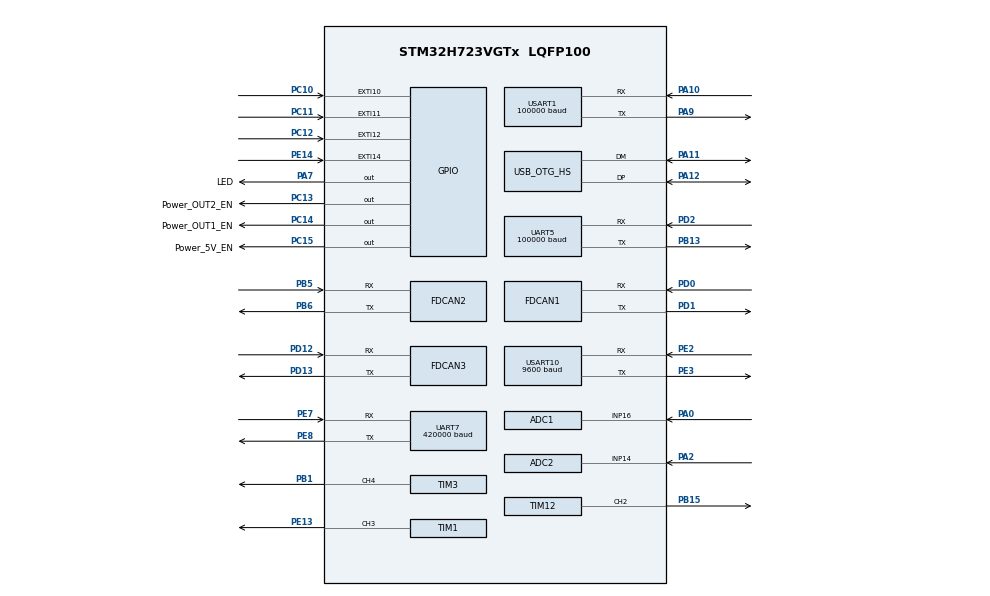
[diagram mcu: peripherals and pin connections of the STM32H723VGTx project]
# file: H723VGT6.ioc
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ADC1.Channel-0\#ChannelRegularConversion=ADC_CHANNEL_16
ADC1.ClockPrescaler=ADC_CLOCK_SYNC_PCLK_DIV1
ADC1.ContinuousConvMode=ENABLE
ADC1.ConversionDataManagement=ADC_CONVERSIONDATA_DMA_CIRCULAR
ADC1.NbrOfConversion=1
ADC1.NbrOfConversionFlag=1
ADC1.OffsetNumber-0\#ChannelRegularConversion=ADC_OFFSET_NONE
ADC1.OffsetSignedSaturation-0\#ChannelRegularConversion=DISABLE
ADC1.Rank-0\#ChannelRegularConversion=1
ADC1.Ratio=1
ADC1.Resolution=ADC_RESOLUTION_12B
ADC1.SamplingTime-0\#ChannelRegularConversion=ADC_SAMPLETIME_64CYCLES_5
ADC1.master=1
ADC2.Channel-0\#ChannelRegularConversion=ADC_CHANNEL_14
ADC2.ClockPrescaler=ADC_CLOCK_SYNC_PCLK_DIV1
ADC2.ContinuousConvMode=ENABLE
ADC2.ConversionDataManagement=ADC_CONVERSIONDATA_DMA_CIRCULAR
ADC2.LowPowerAutoWait=ENABLE
ADC2.NbrOfConversionFlag=1
ADC2.OffsetNumber-0\#ChannelRegularConversion=ADC_OFFSET_NONE
ADC2.OffsetSignedSaturation-0\#ChannelRegularConversion=DISABLE
ADC2.Rank-0\#ChannelRegularConversion=1
ADC2.Resolution=ADC_RESOLUTION_12B
ADC2.SamplingTime-0\#ChannelRegularConversion=ADC_SAMPLETIME_64CYCLES_5
CORTEX_M7.default_mode_Activation=0
Dma.ADC1.6.Direction=DMA_PERIPH_TO_MEMORY
Dma.ADC1.6.EventEnable=DISABLE
Dma.ADC1.6.FIFOMode=DMA_FIFOMODE_DISABLE
Dma.ADC1.6.Instance=DMA1_Stream5
Dma.ADC1.6.MemDataAlignment=DMA_MDATAALIGN_HALFWORD
Dma.ADC1.6.MemInc=DMA_MINC_ENABLE
Dma.ADC1.6.Mode=DMA_CIRCULAR
Dma.ADC1.6.PeriphDataAlignment=DMA_PDATAALIGN_HALFWORD
Dma.ADC1.6.PeriphInc=DMA_PINC_DISABLE
Dma.ADC1.6.Polarity=HAL_DMAMUX_REQ_GEN_RISING
Dma.ADC1.6.Priority=DMA_PRIORITY_HIGH
Dma.ADC1.6.RequestNumber=1
Dma.ADC1.6.SignalID=NONE
Dma.ADC1.6.SyncEnable=DISABLE
Dma.ADC1.6.SyncPolarity=HAL_DMAMUX_SYNC_NO_EVENT
Dma.ADC1.6.SyncRequestNumber=1
Dma.ADC1.6.SyncSignalID=NONE
Dma.ADC2.7.Direction=DMA_PERIPH_TO_MEMORY
Dma.ADC2.7.EventEnable=DISABLE
Dma.ADC2.7.FIFOMode=DMA_FIFOMODE_DISABLE
Dma.ADC2.7.Instance=DMA1_Stream6
Dma.ADC2.7.MemDataAlignment=DMA_MDATAALIGN_HALFWORD
Dma.ADC2.7.MemInc=DMA_MINC_ENABLE
Dma.ADC2.7.Mode=DMA_CIRCULAR
Dma.ADC2.7.PeriphDataAlignment=DMA_PDATAALIGN_HALFWORD
Dma.ADC2.7.PeriphInc=DMA_PINC_DISABLE
Dma.ADC2.7.Polarity=HAL_DMAMUX_REQ_GEN_RISING
Dma.ADC2.7.Priority=DMA_PRIORITY_HIGH
Dma.ADC2.7.RequestNumber=1
Dma.ADC2.7.SignalID=NONE
Dma.ADC2.7.SyncEnable=DISABLE
Dma.ADC2.7.SyncPolarity=HAL_DMAMUX_SYNC_NO_EVENT
Dma.ADC2.7.SyncRequestNumber=1
Dma.ADC2.7.SyncSignalID=NONE
Dma.Request0=USART1_RX
Dma.Request1=USART1_TX
Dma.Request2=USART10_RX
Dma.Request3=USART10_TX
Dma.Request4=UART5_RX
Dma.Request5=UART7_RX
Dma.Request6=ADC1
Dma.Request7=ADC2
Dma.UART5_RX.4.Direction=DMA_PERIPH_TO_MEMORY
Dma.UART5_RX.4.EventEnable=DISABLE
Dma.UART5_RX.4.FIFOMode=DMA_FIFOMODE_DISABLE
Dma.UART5_RX.4.Instance=DMA2_Stream0
Dma.UART5_RX.4.MemDataAlignment=DMA_MDATAALIGN_BYTE
Dma.UART5_RX.4.MemInc=DMA_MINC_ENABLE
Dma.UART5_RX.4.Mode=DMA_CIRCULAR
Dma.UART5_RX.4.PeriphDataAlignment=DMA_PDATAALIGN_BYTE
Dma.UART5_RX.4.PeriphInc=DMA_PINC_DISABLE
Dma.UART5_RX.4.Polarity=HAL_DMAMUX_REQ_GEN_RISING
Dma.UART5_RX.4.Priority=DMA_PRIORITY_VERY_HIGH
Dma.UART5_RX.4.RequestNumber=1
Dma.UART5_RX.4.SignalID=NONE
Dma.UART5_RX.4.SyncEnable=DISABLE
Dma.UART5_RX.4.SyncPolarity=HAL_DMAMUX_SYNC_NO_EVENT
Dma.UART5_RX.4.SyncRequestNumber=1
Dma.UART5_RX.4.SyncSignalID=NONE
Dma.UART7_RX.5.Direction=DMA_PERIPH_TO_MEMORY
Dma.UART7_RX.5.EventEnable=DISABLE
Dma.UART7_RX.5.FIFOMode=DMA_FIFOMODE_DISABLE
Dma.UART7_RX.5.Instance=DMA1_Stream0
Dma.UART7_RX.5.MemDataAlignment=DMA_MDATAALIGN_BYTE
Dma.UART7_RX.5.MemInc=DMA_MINC_ENABLE
Dma.UART7_RX.5.Mode=DMA_CIRCULAR
Dma.UART7_RX.5.PeriphDataAlignment=DMA_PDATAALIGN_BYTE
Dma.UART7_RX.5.PeriphInc=DMA_PINC_DISABLE
Dma.UART7_RX.5.Polarity=HAL_DMAMUX_REQ_GEN_RISING
Dma.UART7_RX.5.Priority=DMA_PRIORITY_VERY_HIGH
Dma.UART7_RX.5.RequestNumber=1
Dma.UART7_RX.5.SignalID=NONE
Dma.UART7_RX.5.SyncEnable=DISABLE
Dma.UART7_RX.5.SyncPolarity=HAL_DMAMUX_SYNC_NO_EVENT
Dma.UART7_RX.5.SyncRequestNumber=1
Dma.UART7_RX.5.SyncSignalID=NONE
Dma.USART10_RX.2.Direction=DMA_PERIPH_TO_MEMORY
Dma.USART10_RX.2.EventEnable=DISABLE
Dma.USART10_RX.2.FIFOMode=DMA_FIFOMODE_DISABLE
Dma.USART10_RX.2.Instance=DMA1_Stream3
Dma.USART10_RX.2.MemDataAlignment=DMA_MDATAALIGN_BYTE
Dma.USART10_RX.2.MemInc=DMA_MINC_ENABLE
Dma.USART10_RX.2.Mode=DMA_NORMAL
Dma.USART10_RX.2.PeriphDataAlignment=DMA_PDATAALIGN_BYTE
Dma.USART10_RX.2.PeriphInc=DMA_PINC_DISABLE
Dma.USART10_RX.2.Polarity=HAL_DMAMUX_REQ_GEN_RISING
Dma.USART10_RX.2.Priority=DMA_PRIORITY_LOW
Dma.USART10_RX.2.RequestNumber=1
Dma.USART10_RX.2.SignalID=NONE
Dma.USART10_RX.2.SyncEnable=DISABLE
Dma.USART10_RX.2.SyncPolarity=HAL_DMAMUX_SYNC_NO_EVENT
Dma.USART10_RX.2.SyncRequestNumber=1
Dma.USART10_RX.2.SyncSignalID=NONE
Dma.USART10_TX.3.Direction=DMA_MEMORY_TO_PERIPH
Dma.USART10_TX.3.EventEnable=DISABLE
Dma.USART10_TX.3.FIFOMode=DMA_FIFOMODE_DISABLE
Dma.USART10_TX.3.Instance=DMA1_Stream4
Dma.USART10_TX.3.MemDataAlignment=DMA_MDATAALIGN_BYTE
Dma.USART10_TX.3.MemInc=DMA_MINC_ENABLE
Dma.USART10_TX.3.Mode=DMA_NORMAL
Dma.USART10_TX.3.PeriphDataAlignment=DMA_PDATAALIGN_BYTE
Dma.USART10_TX.3.PeriphInc=DMA_PINC_DISABLE
Dma.USART10_TX.3.Polarity=HAL_DMAMUX_REQ_GEN_RISING
Dma.USART10_TX.3.Priority=DMA_PRIORITY_LOW
Dma.USART10_TX.3.RequestNumber=1
Dma.USART10_TX.3.SignalID=NONE
Dma.USART10_TX.3.SyncEnable=DISABLE
Dma.USART10_TX.3.SyncPolarity=HAL_DMAMUX_SYNC_NO_EVENT
Dma.USART10_TX.3.SyncRequestNumber=1
Dma.USART10_TX.3.SyncSignalID=NONE
Dma.USART1_RX.0.Direction=DMA_PERIPH_TO_MEMORY
Dma.USART1_RX.0.EventEnable=DISABLE
Dma.USART1_RX.0.FIFOMode=DMA_FIFOMODE_DISABLE
Dma.USART1_RX.0.Instance=DMA1_Stream1
Dma.USART1_RX.0.MemDataAlignment=DMA_MDATAALIGN_BYTE
Dma.USART1_RX.0.MemInc=DMA_MINC_ENABLE
Dma.USART1_RX.0.Mode=DMA_NORMAL
Dma.USART1_RX.0.PeriphDataAlignment=DMA_PDATAALIGN_BYTE
Dma.USART1_RX.0.PeriphInc=DMA_PINC_DISABLE
Dma.USART1_RX.0.Polarity=HAL_DMAMUX_REQ_GEN_RISING
Dma.USART1_RX.0.Priority=DMA_PRIORITY_LOW
Dma.USART1_RX.0.RequestNumber=1
Dma.USART1_RX.0.SignalID=NONE
Dma.USART1_RX.0.SyncEnable=DISABLE
Dma.USART1_RX.0.SyncPolarity=HAL_DMAMUX_SYNC_NO_EVENT
Dma.USART1_RX.0.SyncRequestNumber=1
Dma.USART1_RX.0.SyncSignalID=NONE
Dma.USART1_TX.1.Direction=DMA_MEMORY_TO_PERIPH
Dma.USART1_TX.1.EventEnable=DISABLE
Dma.USART1_TX.1.FIFOMode=DMA_FIFOMODE_DISABLE
Dma.USART1_TX.1.Instance=DMA1_Stream2
Dma.USART1_TX.1.MemDataAlignment=DMA_MDATAALIGN_BYTE
Dma.USART1_TX.1.MemInc=DMA_MINC_ENABLE
Dma.USART1_TX.1.Mode=DMA_NORMAL
Dma.USART1_TX.1.PeriphDataAlignment=DMA_PDATAALIGN_BYTE
Dma.USART1_TX.1.PeriphInc=DMA_PINC_DISABLE
Dma.USART1_TX.1.Polarity=HAL_DMAMUX_REQ_GEN_RISING
Dma.USART1_TX.1.Priority=DMA_PRIORITY_LOW
Dma.USART1_TX.1.RequestNumber=1
Dma.USART1_TX.1.SignalID=NONE
Dma.USART1_TX.1.SyncEnable=DISABLE
Dma.USART1_TX.1.SyncPolarity=HAL_DMAMUX_SYNC_NO_EVENT
Dma.USART1_TX.1.SyncRequestNumber=1
Dma.USART1_TX.1.SyncSignalID=NONE
FDCAN1.AutoRetransmission=ENABLE
FDCAN1.CalculateBaudRateNominal=1000000
FDCAN1.CalculateTimeBitNominal=1000
FDCAN1.CalculateTimeQuantumNominal=25.0
FDCAN1.DataPrescaler=3
FDCAN1.DataSyncJumpWidth=10
FDCAN1.DataTimeSeg1=29
FDCAN1.DataTimeSeg2=10
FDCAN1.ExtFiltersNbr=12
FDCAN1.MessageRAMOffset=0
FDCAN1.NominalPrescaler=3
FDCAN1.NominalSyncJumpWidth=10
FDCAN1.NominalTimeSeg1=29
FDCAN1.NominalTimeSeg2=10
FDCAN1.ProtocolException=ENABLE
FDCAN1.RxFifo0ElmtsNbr=8
FDCAN1.RxFifo1ElmtsNbr=8
FDCAN1.StdFiltersNbr=12
FDCAN1.TxFifoQueueElmtsNbr=32
FDCAN2.AutoRetransmission=ENABLE
FDCAN2.CalculateBaudRateNominal=1000000
FDCAN2.CalculateTimeBitNominal=1000
FDCAN2.CalculateTimeQuantumNominal=25.0
FDCAN2.DataPrescaler=3
FDCAN2.DataSyncJumpWidth=10
FDCAN2.DataTimeSeg1=29
FDCAN2.DataTimeSeg2=10
FDCAN2.ExtFiltersNbr=12
FDCAN2.MessageRAMOffset=0
FDCAN2.NominalPrescaler=3
FDCAN2.NominalSyncJumpWidth=10
FDCAN2.NominalTimeSeg1=29
FDCAN2.NominalTimeSeg2=10
FDCAN2.ProtocolException=ENABLE
FDCAN2.RxFifo0ElmtsNbr=8
FDCAN2.RxFifo1ElmtsNbr=8
FDCAN2.StdFiltersNbr=12
FDCAN2.TxFifoQueueElmtsNbr=32
FDCAN3.AutoRetransmission=ENABLE
FDCAN3.CalculateBaudRateNominal=1000000
FDCAN3.CalculateTimeBitNominal=1000
FDCAN3.CalculateTimeQuantumNominal=25.0
FDCAN3.DataPrescaler=3
FDCAN3.DataSyncJumpWidth=10
FDCAN3.DataTimeSeg1=29
FDCAN3.DataTimeSeg2=10
FDCAN3.ExtFiltersNbr=0
FDCAN3.MessageRAMOffset=1700
FDCAN3.NominalPrescaler=3
FDCAN3.NominalSyncJumpWidth=10
FDCAN3.NominalTimeSeg1=29
FDCAN3.NominalTimeSeg2=10
FDCAN3.ProtocolException=ENABLE
FDCAN3.RxFifo0ElmtsNbr=8
FDCAN3.RxFifo1ElmtsNbr=8
FDCAN3.StdFiltersNbr=0
FDCAN3.TxFifoQueueElmtsNbr=32
Mcu.Family=STM32H7
Mcu.Name=STM32H723VGTx
Mcu.Package=LQFP100
NVIC.DMA1_Stream0_IRQn=true\:0\:0\:false\:false\:true\:false\:true\:true
NVIC.DMA1_Stream1_IRQn=true\:0\:0\:false\:false\:true\:false\:true\:true
NVIC.DMA1_Stream2_IRQn=true\:0\:0\:false\:false\:true\:false\:true\:true
NVIC.DMA1_Stream3_IRQn=true\:0\:0\:false\:false\:true\:false\:true\:true
NVIC.DMA1_Stream4_IRQn=true\:0\:0\:false\:false\:true\:false\:true\:true
NVIC.DMA1_Stream5_IRQn=true\:0\:0\:false\:false\:true\:false\:true\:true
NVIC.DMA1_Stream6_IRQn=true\:0\:0\:false\:false\:true\:false\:true\:true
NVIC.DMA2_Stream0_IRQn=true\:0\:0\:false\:false\:true\:false\:true\:true
NVIC.EXTI15_10_IRQn=true\:0\:0\:false\:false\:true\:true\:true\:true
NVIC.FDCAN1_IT0_IRQn=true\:0\:0\:false\:false\:true\:true\:true\:true
NVIC.FDCAN2_IT0_IRQn=true\:0\:0\:false\:false\:true\:true\:true\:true
NVIC.FDCAN3_IT0_IRQn=true\:0\:0\:false\:false\:true\:true\:true\:true
NVIC.OTG_HS_IRQn=true\:0\:0\:false\:false\:true\:true\:true\:true
NVIC.PriorityGroup=NVIC_PRIORITYGROUP_4
NVIC.TIM2_IRQn=true\:0\:0\:false\:false\:true\:true\:true\:true
NVIC.TIM4_IRQn=true\:0\:0\:false\:false\:true\:true\:true\:true
NVIC.TIM5_IRQn=true\:1\:0\:true\:false\:true\:true\:true\:true
NVIC.UART5_IRQn=true\:0\:0\:false\:false\:true\:true\:true\:true
NVIC.USART10_IRQn=true\:0\:0\:false\:false\:true\:true\:true\:true
NVIC.USART1_IRQn=true\:0\:0\:false\:false\:true\:true\:true\:true
PA0.Mode=IN16-Single-Ended
PA0.Signal=ADC1_INP16
PA10.Mode=Asynchronous
PA10.Signal=USART1_RX
PA11.Mode=Device_Only_FS
PA11.Signal=USB_OTG_HS_DM
PA12.Mode=Device_Only_FS
PA12.Signal=USB_OTG_HS_DP
PA13(JTMS/SWDIO).Mode=Serial_Wire
PA13(JTMS/SWDIO).Signal=DEBUG_JTMS-SWDIO
PA14(JTCK/SWCLK).Mode=Serial_Wire
PA14(JTCK/SWCLK).Signal=DEBUG_JTCK-SWCLK
PA2.Signal=ADCx_INP14
PA7.GPIO_Label=LED
PA7.Signal=GPIO_Output
PA9.Mode=Asynchronous
PA9.Signal=USART1_TX
PB1.Signal=S_TIM3_CH4
PB13.Mode=Asynchronous
PB13.Signal=UART5_TX
PB15.Signal=S_TIM12_CH2
PB5.Mode=FDCAN_Activate
PB5.Signal=FDCAN2_RX
PB6.Mode=FDCAN_Activate
PB6.Signal=FDCAN2_TX
PC10.GPIO_ModeDefaultEXTI=GPIO_MODE_IT_FALLING
PC10.GPIO_PuPd=GPIO_PULLUP
PC10.Signal=GPXTI10
PC11.GPIO_ModeDefaultEXTI=GPIO_MODE_IT_FALLING
PC11.GPIO_PuPd=GPIO_PULLUP
PC11.Signal=GPXTI11
PC12.GPIO_ModeDefaultEXTI=GPIO_MODE_IT_FALLING
PC12.GPIO_PuPd=GPIO_PULLUP
PC12.Signal=GPXTI12
PC13.GPIO_Label=Power_OUT2_EN
PC13.GPIO_PuPd=GPIO_PULLDOWN
PC13.Signal=GPIO_Output
PC14-OSC32_IN.GPIO_Label=Power_OUT1_EN
PC14-OSC32_IN.GPIO_PuPd=GPIO_PULLDOWN
PC14-OSC32_IN.PinState=GPIO_PIN_SET
PC14-OSC32_IN.Signal=GPIO_Output
PC15-OSC32_OUT.GPIO_Label=Power_5V_EN
PC15-OSC32_OUT.GPIO_PuPd=GPIO_PULLUP
PC15-OSC32_OUT.Signal=GPIO_Output
PD0.Mode=FDCAN_Activate
PD0.Signal=FDCAN1_RX
PD1.Mode=FDCAN_Activate
PD1.Signal=FDCAN1_TX
PD12.Mode=FDCAN_Activate
PD12.Signal=FDCAN3_RX
PD13.Mode=FDCAN_Activate
PD13.Signal=FDCAN3_TX
PD2.Mode=Asynchronous
PD2.Signal=UART5_RX
PE13.Signal=S_TIM1_CH3
PE14.GPIO_ModeDefaultEXTI=GPIO_MODE_IT_FALLING
PE14.GPIO_PuPd=GPIO_PULLUP
PE14.Signal=GPXTI14
PE2.Mode=Asynchronous
PE2.Signal=USART10_RX
PE3.Mode=Asynchronous
PE3.Signal=USART10_TX
PE7.Mode=Asynchronous
PE7.Signal=UART7_RX
PE8.Mode=Asynchronous
PE8.Signal=UART7_TX
PH0-OSC_IN.Mode=HSE-External-Oscillator
PH0-OSC_IN.Signal=RCC_OSC_IN
PH1-OSC_OUT.Mode=HSE-External-Oscillator
PH1-OSC_OUT.Signal=RCC_OSC_OUT
ProjectManager.HeapSize=0x400
ProjectManager.StackSize=0x2000
ProjectManager.TargetToolchain=CMake
RCC.ADCFreq_Value=100000000
RCC.APB1Freq_Value=120000000
RCC.APB2Freq_Value=120000000
RCC.APB3Freq_Value=120000000
RCC.APB4Freq_Value=120000000
RCC.CortexFreq_Value=480000000
RCC.D1PPRE=RCC_APB3_DIV2
RCC.D2PPRE1=RCC_APB1_DIV2
RCC.D2PPRE2=RCC_APB2_DIV2
RCC.D3PPRE=RCC_APB4_DIV2
RCC.DIVM1=2
RCC.DIVM2=24
RCC.DIVN1=40
RCC.DIVN2=200
RCC.DIVP1=1
RCC.DIVQ1=4
RCC.HCLKFreq_Value=240000000
RCC.HPRE=RCC_HCLK_DIV2
RCC.HSE_VALUE=24000000
RCC.PLL2FRACN=0
RCC.PLL3FRACN=0
RCC.PLLFRACN=0
RCC.PLLSourceVirtual=RCC_PLLSOURCE_HSE
RCC.SYSCLKFreq_VALUE=480000000
RCC.SYSCLKSource=RCC_SYSCLKSOURCE_PLLCLK
RCC.USBCLockSelection=RCC_USBCLKSOURCE_HSI48
RCC.USBFreq_Value=48000000
SH.ADCx_INP14.0=ADC2_INP14,IN14-Single-Ended
SH.S_TIM12_CH2.0=TIM12_CH2,PWM Generation2 CH2
SH.S_TIM1_CH3.0=TIM1_CH3,PWM Generation3 CH3
SH.S_TIM3_CH4.0=TIM3_CH4,PWM Generation4 CH4
TIM1.Channel-PWM\ Generation3\ CH3=TIM_CHANNEL_3
TIM1.Period=20000-1
TIM1.Prescaler=239
TIM12.AutoReloadPreload=TIM_AUTORELOAD_PRELOAD_ENABLE
TIM12.Channel-PWM\ Generation2\ CH2=TIM_CHANNEL_2
TIM12.Period=1000-1
TIM12.Prescaler=240-1
TIM2.AutoReloadPreload=TIM_AUTORELOAD_PRELOAD_ENABLE
TIM2.Period=1000-1
TIM2.Prescaler=240-1
TIM3.Channel-PWM\ Generation4\ CH4=TIM_CHANNEL_4
TIM3.OCFastMode_PWM-PWM\ Generation4\ CH4=TIM_OCFAST_ENABLE
TIM3.Period=255
TIM4.Period=100-1
TIM4.Prescaler=240-1
TIM5.Period=1000-1
TIM5.Prescaler=240-1
UART5.BaudRate=100000
UART5.Mode=MODE_RX
UART5.Parity=PARITY_EVEN
UART5.StopBits=UART_STOPBITS_2
UART5.WordLength=WORDLENGTH_9B
UART7.BaudRate=420000
USART1.BaudRate=100000
USART1.Parity=PARITY_EVEN
USART1.RxPinLevelInvertParam=ADVFEATURE_RXINV_ENABLE
USART1.StopBits=STOPBITS_2
USART1.VirtualMode-Asynchronous=VM_ASYNC
USART10.BaudRate=9600
USART10.VirtualMode=VM_ASYNC
USB_DEVICE.CLASS_NAME_HS=CDC
USB_DEVICE.VirtualMode=Cdc
USB_DEVICE.VirtualModeHS=Cdc_HS
USB_OTG_HS.VirtualMode-Device_Only_FS=Device_Only_FS
VP_MEMORYMAP_VS_MEMORYMAP.Mode=CurAppReg
VP_TIM2_VS_ClockSourceINT.Mode=Internal
VP_TIM4_VS_ClockSourceINT.Mode=Internal
VP_TIM5_VS_ClockSourceINT.Mode=Internal
VP_USB_DEVICE_VS_USB_DEVICE_CDC_HS.Mode=CDC_HS
board=custom

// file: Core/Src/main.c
/* USER CODE BEGIN Header */
/**
  ******************************************************************************
  * @file           : main.c
  * @brief          : Main program body
  ******************************************************************************
  * @attention
  *
  * Copyright (c) 2026 STMicroelectronics.
  * All rights reserved.
  *
  * This software is licensed under terms that can be found in the LICENSE file
  * in the root directory of this software component.
  * If no LICENSE file comes with this software, it is provided AS-IS.
  *
  ******************************************************************************
  */
/* USER CODE END Header */
#include "main.h"
#include "adc.h"
#include "dma.h"
#include "fdcan.h"
#include "tim.h"
#include "usart.h"
#include "usb_device.h"
#include "gpio.h"

/* USER CODE BEGIN Includes */
#include "tsk_config_and_callback.h"
/* USER CODE END Includes */

void SystemClock_Config(void);

int main(void)
{

  /* MCU Configuration--------------------------------------------------------*/

  /* Reset of all peripherals, Initializes the Flash interface and the Systick. */
  HAL_Init();

  /* Configure the system clock */
  SystemClock_Config();

  /* Initialize all configured peripherals */
  MX_GPIO_Init();
  MX_DMA_Init();
  MX_TIM5_Init();
  MX_FDCAN1_Init();
  MX_TIM3_Init();
  MX_TIM12_Init();
  MX_FDCAN2_Init();
  MX_FDCAN3_Init();
  MX_UART5_Init();
  MX_USART1_UART_Init();
  MX_USART10_UART_Init();
  MX_TIM4_Init();
  MX_UART7_Init();
  MX_ADC1_Init();
  MX_USB_DEVICE_Init();
  MX_TIM1_Init();
  MX_ADC2_Init();
  MX_TIM2_Init();
  /* USER CODE BEGIN 2 */
  TaskInit();
  /* USER CODE END 2 */

  /* Infinite loop */
  while (1)
  {

    /* USER CODE BEGIN 3 */
    TaskLoop();
  }
  /* USER CODE END 3 */
}

void SystemClock_Config(void)
{
  RCC_OscInitTypeDef RCC_OscInitStruct = {0};
  RCC_ClkInitTypeDef RCC_ClkInitStruct = {0};

  /** Supply configuration update enable
  */
  HAL_PWREx_ConfigSupply(PWR_LDO_SUPPLY);

  /** Configure the main internal regulator output voltage
  */
  __HAL_PWR_VOLTAGESCALING_CONFIG(PWR_REGULATOR_VOLTAGE_SCALE0);

  while(!__HAL_PWR_GET_FLAG(PWR_FLAG_VOSRDY)) {}

  /** Initializes the RCC Oscillators according to the specified parameters
  * in the RCC_OscInitTypeDef structure.
  */
  RCC_OscInitStruct.OscillatorType = RCC_OSCILLATORTYPE_HSI48|RCC_OSCILLATORTYPE_HSE;
  RCC_OscInitStruct.HSEState = RCC_HSE_ON;
  RCC_OscInitStruct.HSI48State = RCC_HSI48_ON;
  RCC_OscInitStruct.PLL.PLLState = RCC_PLL_ON;
  RCC_OscInitStruct.PLL.PLLSource = RCC_PLLSOURCE_HSE;
  RCC_OscInitStruct.PLL.PLLM = 2;
  RCC_OscInitStruct.PLL.PLLN = 40;
  RCC_OscInitStruct.PLL.PLLP = 1;
  RCC_OscInitStruct.PLL.PLLQ = 4;
  RCC_OscInitStruct.PLL.PLLR = 2;
  RCC_OscInitStruct.PLL.PLLRGE = RCC_PLL1VCIRANGE_3;
  RCC_OscInitStruct.PLL.PLLVCOSEL = RCC_PLL1VCOWIDE;
  RCC_OscInitStruct.PLL.PLLFRACN = 0;
  if (HAL_RCC_OscConfig(&RCC_OscInitStruct) != HAL_OK)
  {
    Error_Handler();
  }

  /** Initializes the CPU, AHB and APB buses clocks
  */
  RCC_ClkInitStruct.ClockType = RCC_CLOCKTYPE_HCLK|RCC_CLOCKTYPE_SYSCLK
                              |RCC_CLOCKTYPE_PCLK1|RCC_CLOCKTYPE_PCLK2
                              |RCC_CLOCKTYPE_D3PCLK1|RCC_CLOCKTYPE_D1PCLK1;
  RCC_ClkInitStruct.SYSCLKSource = RCC_SYSCLKSOURCE_PLLCLK;
  RCC_ClkInitStruct.SYSCLKDivider = RCC_SYSCLK_DIV1;
  RCC_ClkInitStruct.AHBCLKDivider = RCC_HCLK_DIV2;
  RCC_ClkInitStruct.APB3CLKDivider = RCC_APB3_DIV2;
  RCC_ClkInitStruct.APB1CLKDivider = RCC_APB1_DIV2;
  RCC_ClkInitStruct.APB2CLKDivider = RCC_APB2_DIV2;
  RCC_ClkInitStruct.APB4CLKDivider = RCC_APB4_DIV2;

  if (HAL_RCC_ClockConfig(&RCC_ClkInitStruct, FLASH_LATENCY_3) != HAL_OK)
  {
    Error_Handler();
  }
}

void Error_Handler(void)
{
  __disable_irq();
  while (1)
  {
  }
}
